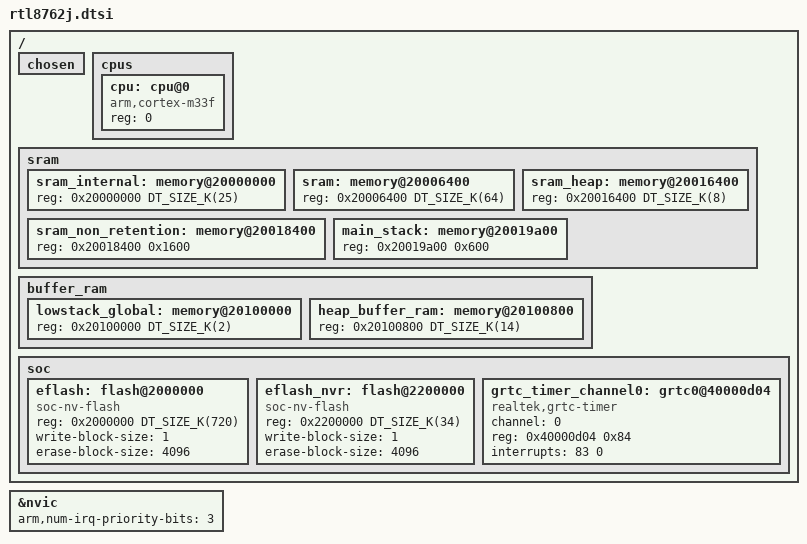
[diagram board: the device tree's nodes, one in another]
#include <mem.h>
#include <arm/armv8-m.dtsi>
#include <freq.h>

/ {
	chosen {
	};

	cpus {
		#address-cells = <1>;
		#size-cells = <0>;

		cpu: cpu@0 {
			device_type = "cpu";
			compatible = "arm,cortex-m33f";
			reg = <0>;
			#address-cells = <1>;
			#size-cells = <1>;
		};
	};


	sram {
		#address-cells = <1>;
		#size-cells = <1>;
		//0x20000000 ~ 0x2001a000
		sram_internal: memory@20000000 {
			device_type = "internal sram region";
			reg = <0x20000000 DT_SIZE_K(25)>;
		};
		sram: memory@20006400 {
			device_type = "sram region";
			reg = <0x20006400 DT_SIZE_K(64)>;
		};
		sram_heap: memory@20016400 {
			device_type = "sram heap region";
			reg = <0x20016400 DT_SIZE_K(8)>;
		};
		sram_non_retention: memory@20018400 {
			device_type = "sram (non-retention) region";
			reg = <0x20018400 0x1600>;//5.5k
		};
		main_stack: memory@20019a00 {
			device_type = "main stack region";
			reg = <0x20019a00 0x600>;//1.5k
		};
	};

	buffer_ram {
		#address-cells = <1>;
		#size-cells = <1>;
		//0x20100000 ~ 0x20104000
		lowstack_global: memory@20100000 {
			device_type = "lowstack global region";
			reg = <0x20100000 DT_SIZE_K(2)>;
		};
		heap_buffer_ram: memory@20100800 {
			device_type = "heap buffer_ram region";
			reg = <0x20100800 DT_SIZE_K(14)>;
		};
	};

	soc {

		eflash: flash@2000000 {
			compatible = "soc-nv-flash";
			reg = <0x2000000 DT_SIZE_K(720)>;
			write-block-size = <1>;
			erase-block-size = <4096>;
		};

		eflash_nvr: flash@2200000 {
			compatible = "soc-nv-flash";
			reg = <0x2200000 DT_SIZE_K(34)>;
			write-block-size = <1>;
			erase-block-size = <4096>;
		};

		// trace: memory@18080000 {
		// 	compatible = "zephyr,memory-region";
		// 	reg = <0x18080000 0x80000>;
		// 	zephyr,memory-region = "TRACE";
		// };

		grtc_timer_channel0: grtc0@40000d04 {
			compatible = "realtek,grtc-timer";
			channel = <0>;
			reg = <0x40000d04 0x84>;
			interrupts = <83 0>;
			status = "okay";
		};
	};

};

&nvic {
	arm,num-irq-priority-bits = <3>;
};
